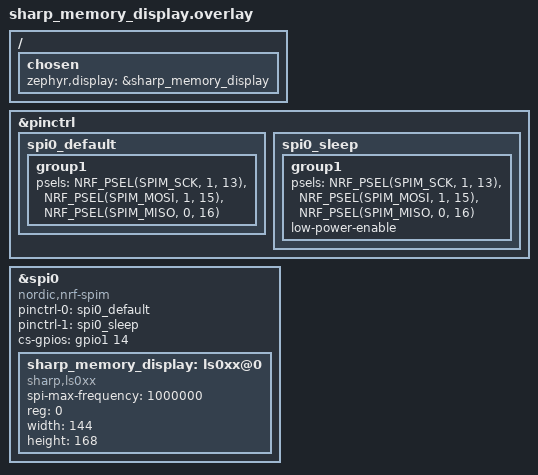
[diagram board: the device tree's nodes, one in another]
/*
 * Copyright (c) 2022 The ZMK Contributors
 *
 * SPDX-License-Identifier: MIT
 */

 &pinctrl {
    spi0_default: spi0_default {
        group1 {
            psels = <NRF_PSEL(SPIM_SCK, 1, 13)>,
                <NRF_PSEL(SPIM_MOSI, 1, 15)>,
                <NRF_PSEL(SPIM_MISO, 0, 16)>;
        };
    };
    spi0_sleep: spi0_sleep {
        group1 {
            psels = <NRF_PSEL(SPIM_SCK, 1, 13)>,
                <NRF_PSEL(SPIM_MOSI, 1, 15)>,
                <NRF_PSEL(SPIM_MISO, 0, 16)>;
            low-power-enable;
        };
    };
};

sharp_memory_display_spi: &spi0 {
    compatible = "nordic,nrf-spim";
    pinctrl-0 = <&spi0_default>;
    pinctrl-1 = <&spi0_sleep>;
    pinctrl-names = "default", "sleep";
    cs-gpios = <&gpio1 14 GPIO_ACTIVE_HIGH>;
};

&sharp_memory_display_spi {
    status = "okay";
    sharp_memory_display: ls0xx@0 {
        compatible = "sharp,ls0xx";
        spi-max-frequency = <1000000>;
        reg = <0>;
        width = <144>;
        height = <168>;
    };
};

/ {
    chosen {
        zephyr,display = &sharp_memory_display;
    };
};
